# HDSC_HC32F480 register map
Vendor: HDSC Co.Ltd; Series: ARMCM4; File version: 1.2
CPU: CM0 r0p0, little endian, no MPU, no FPU, 3 interrupt priority bits
Registers are 16-bit, read-write, reset 0x0 unless marked. A register's access mark holds for its fields unless they carry their own. Offsets are from the block's base; [hi:lo] are bit positions; {n}, {i} and the like mark numbered series.

## ETH
Base 0x40050000
0x5410 MAC_IFCONFR 8-bit
  [0] IFSEL
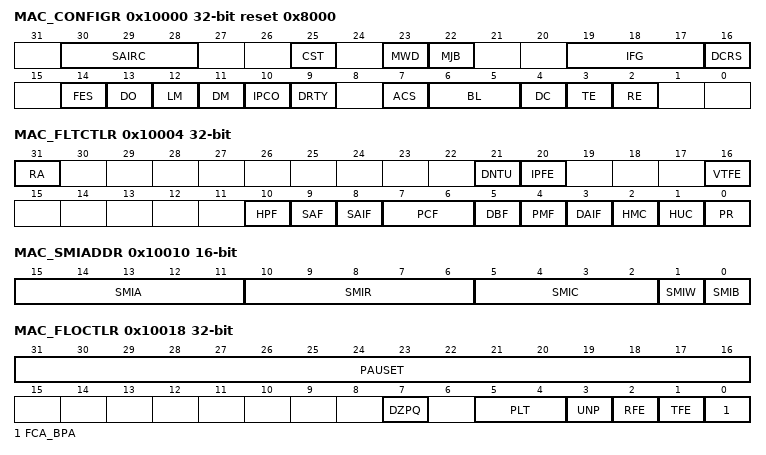
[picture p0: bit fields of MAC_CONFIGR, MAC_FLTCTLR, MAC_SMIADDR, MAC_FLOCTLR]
0x10000 MAC_CONFIGR 32-bit reset 0x8000
  [30:28] SAIRC, [25] CST, [23] MWD, [22] MJB, [19:17] IFG, [16] DCRS, [14] FES, [13] DO, [12] LM, [11] DM, [10] IPCO, [9] DRTY, [7] ACS, [6:5] BL, [4] DC, [3] TE, [2] RE
0x10004 MAC_FLTCTLR 32-bit
  [31] RA, [21] DNTU, [20] IPFE, [16] VTFE, [10] HPF, [9] SAF, [8] SAIF, [7:6] PCF, [5] DBF, [4] PMF, [3] DAIF, [2] HMC, [1] HUC, [0] PR
0x10008 MAC_HASHTHR 32-bit
0x1000C MAC_HASHTLR 32-bit
0x10010 MAC_SMIADDR
  [15:11] SMIA, [10:6] SMIR, [5:2] SMIC, [1] SMIW, [0] SMIB
0x10014 MAC_SMIDATR
0x10018 MAC_FLOCTLR 32-bit
  [31:16] PAUSET, [7] DZPQ, [5:4] PLT, [3] UNP, [2] RFE, [1] TFE, [0] FCA_BPA
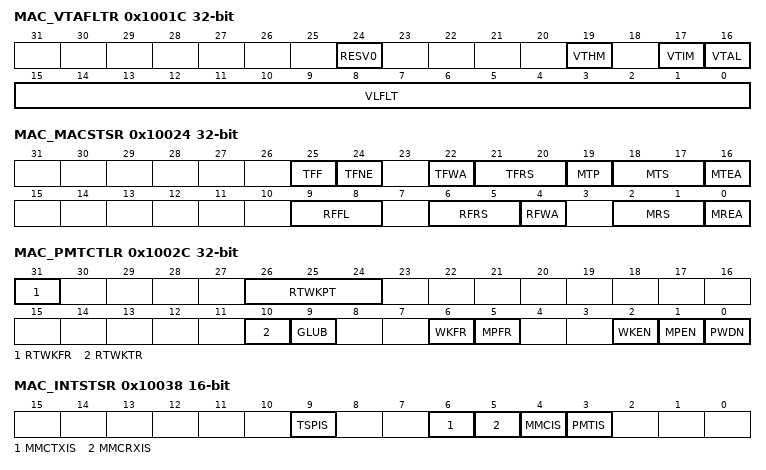
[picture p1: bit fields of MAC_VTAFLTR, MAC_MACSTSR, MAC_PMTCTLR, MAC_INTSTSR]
0x1001C MAC_VTAFLTR 32-bit
  [24] RESV0, [19] VTHM, [17] VTIM, [16] VTAL, [15:0] VLFLT
0x10024 MAC_MACSTSR 32-bit ro
  [25] TFF, [24] TFNE, [22] TFWA, [21:20] TFRS, [19] MTP, [18:17] MTS, [16] MTEA, [9:8] RFFL, [6:5] RFRS, [4] RFWA, [2:1] MRS, [0] MREA
0x10028 MAC_RTWKFFR 32-bit
0x1002C MAC_PMTCTLR 32-bit
  [31] RTWKFR, [26:24] RTWKPT ro, [10] RTWKTR, [9] GLUB, [6] WKFR ro, [5] MPFR ro, [2] WKEN, [1] MPEN, [0] PWDN
0x10038 MAC_INTSTSR ro
  [9] TSPIS, [6] MMCTXIS, [5] MMCRXIS, [4] MMCIS, [3] PMTIS
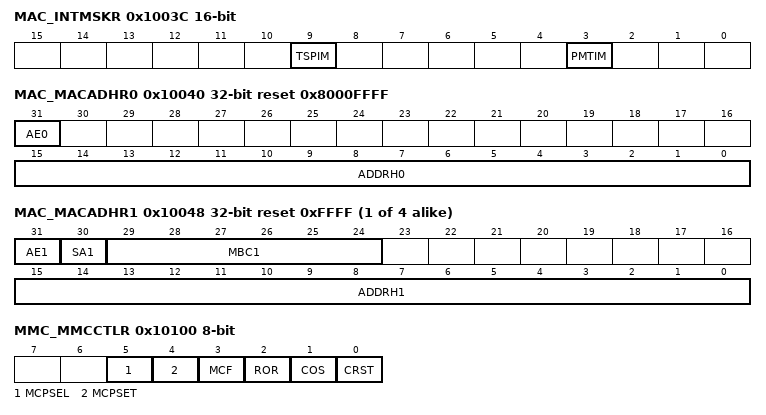
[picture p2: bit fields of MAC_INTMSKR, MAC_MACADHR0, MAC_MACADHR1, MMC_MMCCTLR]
0x1003C MAC_INTMSKR
  [9] TSPIM, [3] PMTIM
0x10040 MAC_MACADHR0 32-bit reset 0x8000FFFF
  [31] AE0 ro, [15:0] ADDRH0
{0x10044+8i} MAC_MACADLR{i} 32-bit reset 0xFFFFFFFF (i=0..4)
{0x10040+8i} MAC_MACADHR{i} 32-bit reset 0xFFFF (i=1..4)
  [31] AE{i}, [30] SA{i}, [29:24] MBC{i}, [15:0] ADDRH{i}
0x10100 MMC_MMCCTLR 8-bit
  [5] MCPSEL, [4] MCPSET, [3] MCF, [2] ROR, [1] COS, [0] CRST
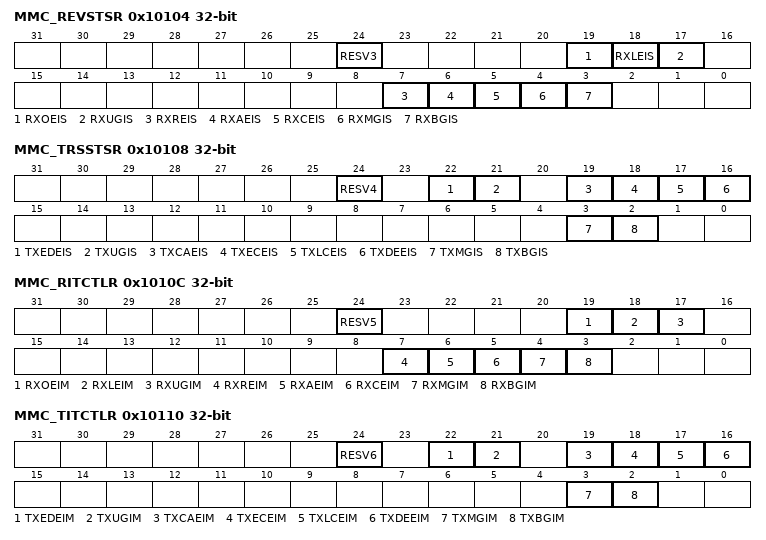
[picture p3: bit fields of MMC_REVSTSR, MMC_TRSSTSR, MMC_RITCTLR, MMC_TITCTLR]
0x10104 MMC_REVSTSR 32-bit ro
  [24] RESV3 rw, [19] RXOEIS, [18] RXLEIS, [17] RXUGIS, [7] RXREIS, [6] RXAEIS, [5] RXCEIS, [4] RXMGIS, [3] RXBGIS
0x10108 MMC_TRSSTSR 32-bit ro
  [24] RESV4 rw, [22] TXEDEIS, [21] TXUGIS, [19] TXCAEIS, [18] TXECEIS, [17] TXLCEIS, [16] TXDEEIS, [3] TXMGIS, [2] TXBGIS
0x1010C MMC_RITCTLR 32-bit
  [24] RESV5, [19] RXOEIM, [18] RXLEIM, [17] RXUGIM, [7] RXREIM, [6] RXAEIM, [5] RXCEIM, [4] RXMGIM, [3] RXBGIM
0x10110 MMC_TITCTLR 32-bit
  [24] RESV6, [22] TXEDEIM, [21] TXUGIM, [19] TXCAEIM, [18] TXECEIM, [17] TXLCEIM, [16] TXDEEIM, [3] TXMGIM, [2] TXBGIM
0x1011C MMC_TXBRGFR
0x10120 MMC_TXMUGFR
0x10154 MMC_TXDEEFR
0x10158 MMC_TXLCEFR
0x1015C MMC_TXECEFR
0x10160 MMC_TXCAEFR
0x10168 MMC_TXUNGFR
0x1016C MMC_TXEDEFR
0x1018C MMC_RXBRGFR
0x10190 MMC_RXMUGFR
0x10194 MMC_RXCREFR
0x10198 MMC_RXALEFR
0x1019C MMC_RXRUEFR
0x101C4 MMC_RXUNGFR
0x101C8 MMC_RXLEEFR
0x101CC MMC_RXOREFR
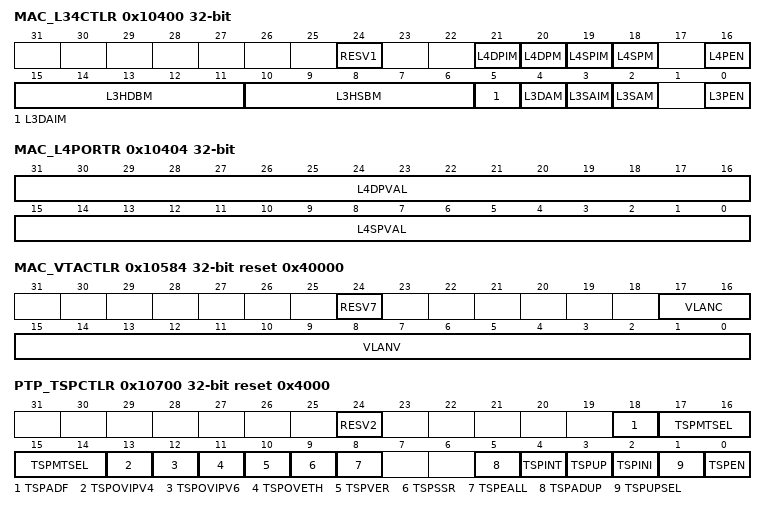
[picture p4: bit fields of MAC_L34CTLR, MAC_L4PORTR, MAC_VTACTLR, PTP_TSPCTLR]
0x10400 MAC_L34CTLR 32-bit
  [24] RESV1, [21] L4DPIM, [20] L4DPM, [19] L4SPIM, [18] L4SPM, [16] L4PEN, [15:11] L3HDBM, [10:6] L3HSBM, [5] L3DAIM, [4] L3DAM, [3] L3SAIM, [2] L3SAM, [0] L3PEN
0x10404 MAC_L4PORTR 32-bit
  [31:16] L4DPVAL, [15:0] L4SPVAL
{0x10410+4i} MAC_L3ADDRR{i} 32-bit (i=0..3)
0x10584 MAC_VTACTLR 32-bit reset 0x40000
  [24] RESV7, [17:16] VLANC, [15:0] VLANV
0x10588 MAC_VLAHTBR
0x10700 PTP_TSPCTLR 32-bit reset 0x4000
  [24] RESV2, [18] TSPADF, [17:14] TSPMTSEL, [13] TSPOVIPV4, [12] TSPOVIPV6, [11] TSPOVETH, [10] TSPVER, [9] TSPSSR, [8] TSPEALL, [5] TSPADUP, [4] TSPINT, [3] TSPUP, [2] TSPINI, [1] TSPUPSEL, [0] TSPEN
0x10704 PTP_TSPNSAR 8-bit
0x10708 PTP_TMSSECR 32-bit
0x1070C PTP_TMSNSER 32-bit
0x10710 PTP_TMUSECR 32-bit
0x10714 PTP_TMUNSER 32-bit
0x10718 PTP_TSPADDR 32-bit
0x1071C PTP_TMTSECR0 32-bit
0x10720 PTP_TMTNSER0 32-bit
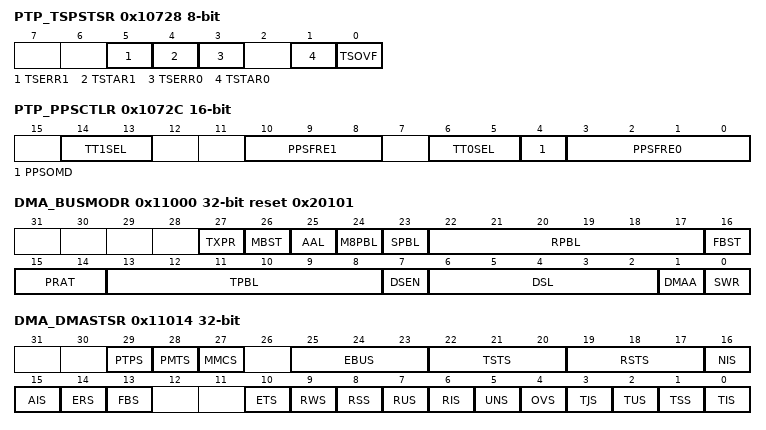
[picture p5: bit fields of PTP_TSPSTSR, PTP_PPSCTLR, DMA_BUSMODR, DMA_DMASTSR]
0x10728 PTP_TSPSTSR 8-bit ro
  [5] TSERR1, [4] TSTAR1, [3] TSERR0, [1] TSTAR0, [0] TSOVF
0x1072C PTP_PPSCTLR
  [14:13] TT1SEL, [10:8] PPSFRE1, [6:5] TT0SEL, [4] PPSOMD, [3:0] PPSFRE0
0x10780 PTP_TMTSECR1 32-bit
0x10784 PTP_TMTNSER1 32-bit
0x11000 DMA_BUSMODR 32-bit reset 0x20101
  [27] TXPR, [26] MBST, [25] AAL, [24] M8PBL, [23] SPBL, [22:17] RPBL, [16] FBST, [15:14] PRAT, [13:8] TPBL, [7] DSEN, [6:2] DSL, [1] DMAA, [0] SWR
0x11004 DMA_TXPOLLR 32-bit
0x11008 DMA_RXPOLLR 32-bit
0x1100C DMA_RXDLADR 32-bit
0x11010 DMA_TXDLADR 32-bit
0x11014 DMA_DMASTSR 32-bit ro
  [29] PTPS, [28] PMTS, [27] MMCS, [25:23] EBUS, [22:20] TSTS, [19:17] RSTS, [16] NIS, [15] AIS, [14] ERS, [13] FBS, [10] ETS, [9] RWS, [8] RSS, [7] RUS, [6] RIS, [5] UNS, [4] OVS, [3] TJS, [2] TUS, [1] TSS, [0] TIS
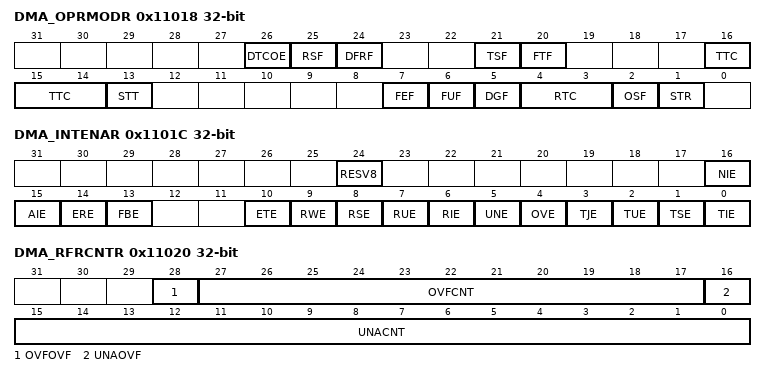
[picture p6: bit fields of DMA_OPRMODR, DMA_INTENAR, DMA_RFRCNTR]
0x11018 DMA_OPRMODR 32-bit
  [26] DTCOE, [25] RSF, [24] DFRF, [21] TSF, [20] FTF, [16:14] TTC, [13] STT, [7] FEF, [6] FUF, [5] DGF, [4:3] RTC, [2] OSF, [1] STR
0x1101C DMA_INTENAR 32-bit
  [24] RESV8, [16] NIE, [15] AIE, [14] ERE, [13] FBE, [10] ETE, [9] RWE, [8] RSE, [7] RUE, [6] RIE, [5] UNE, [4] OVE, [3] TJE, [2] TUE, [1] TSE, [0] TIE
0x11020 DMA_RFRCNTR 32-bit ro
  [28] OVFOVF, [27:17] OVFCNT, [16] UNAOVF, [15:0] UNACNT
0x11024 DMA_REVWDTR 8-bit
0x11048 DMA_CHTXDER 32-bit ro
0x1104C DMA_CHRXDER 32-bit ro
0x11050 DMA_CHTXBFR 32-bit ro
0x11054 DMA_CHRXBFR 32-bit ro
